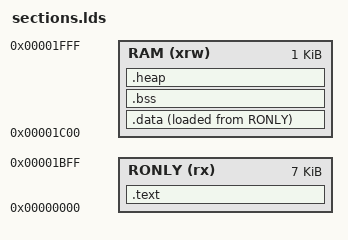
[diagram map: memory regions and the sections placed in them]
MEMORY
{
    RONLY (rx)  : ORIGIN = 0x00000000, LENGTH = 7k
    RAM  (xrw)  : ORIGIN = 7k, LENGTH = 1k
}

SECTIONS {
    /* The program code and other data goes into FLASH */
    .text :
    {
        . = ALIGN(4);
        *(.boot)
    /*    . = 0xC0;		*/
        *(.text)           /* .text sections (code) */
        *(.text*)          /* .text* sections (code) */
        *(.rodata)         /* .rodata sections (constants, strings, etc.) */
        *(.rodata*)        /* .rodata* sections (constants, strings, etc.) */
        *(.srodata)        /* .rodata sections (constants, strings, etc.) */
        *(.srodata*)       /* .rodata* sections (constants, strings, etc.) */
        _etext = .;        /* define a global symbol at end of code */
        _sidata = _etext;  /* This is used by the startup in order to initialize the .data secion */
    } >RONLY

    .data :
    {
        . = ALIGN(4);
        _sdata_values = LOADADDR(.data);
        _sdata = .;        /* create a global symbol at data start; used by startup code in order to initialise the .data section in RAM */
        _ram_start = .;    /* create a global symbol at ram start for garbage collector */
        . = ALIGN(4);
        *(.data)           /* .data sections */
        *(.data*)          /* .data* sections */
        *(.sdata)           /* .sdata sections */
        *(.sdata*)          /* .sdata* sections */
        . = ALIGN(4);
        _edata = .;        /* define a global symbol at data end; used by startup code in order to initialise the .data section in RAM */
    } >RAM AT>RONLY

    /* Uninitialized data section */
    .bss :
    {
        . = ALIGN(4);
        _sbss = .;         /* define a global symbol at bss start; used by startup code */
        *(.bss)
        *(.bss*)
        *(.sbss)
        *(.sbss*)
        *(COMMON)

        . = ALIGN(4);
        _ebss = .;         /* define a global symbol at bss end; used by startup code */
    } >RAM

    /* this is to define the start of the heap, and make sure we have a minimum size */
    .heap :
    {
        . = ALIGN(4);
        _heap_start = .;    /* define a global symbol at heap start */
    } >RAM
    
}
